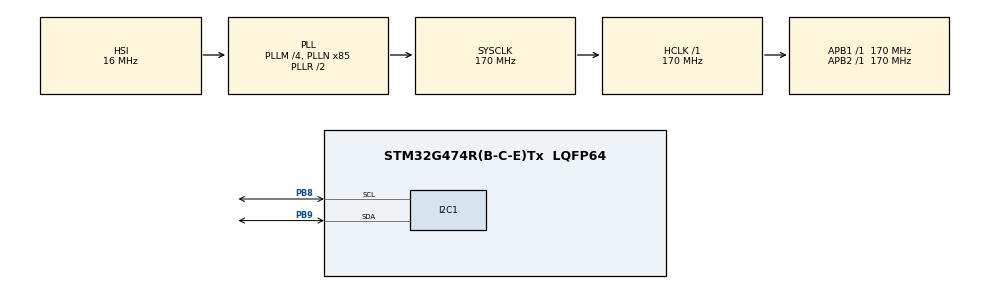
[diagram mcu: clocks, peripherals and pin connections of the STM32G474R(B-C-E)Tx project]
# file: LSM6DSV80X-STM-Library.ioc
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I2C1.Timing=0x40B285C2
Mcu.Family=STM32G4
Mcu.Name=STM32G474R(B-C-E)Tx
Mcu.Package=LQFP64
NUCLEO-G474RE.BUTTON=1
NUCLEO-G474RE.LD2=true
NUCLEO-G474RE.VCP=true
NVIC.EXTI15_10_IRQn=true\:0\:0\:false\:false\:true\:false\:true\:true
NVIC.PriorityGroup=NVIC_PRIORITYGROUP_4
PA13.GPIO_Label=T_SWDIO
PA13.Mode=Serial_Wire
PA13.Signal=SYS_JTMS-SWDIO
PA14.GPIO_Label=T_SWCLK
PA14.Mode=Serial_Wire
PA14.Signal=SYS_JTCK-SWCLK
PA2.Signal=LPUART1_TX
PA3.Signal=LPUART1_RX
PB3.GPIO_Label=T_SWO
PB3.Signal=SYS_JTDO-SWO
PB8-BOOT0.GPIO_Pu=GPIO_PULLUP
PB8-BOOT0.GPIO_Speed=GPIO_SPEED_FREQ_VERY_HIGH
PB8-BOOT0.Mode=I2C
PB8-BOOT0.Signal=I2C1_SCL
PB9.GPIO_Pu=GPIO_PULLUP
PB9.GPIO_Speed=GPIO_SPEED_FREQ_VERY_HIGH
PB9.Mode=I2C
PB9.Signal=I2C1_SDA
PC14-OSC32_IN.GPIO_Label=RCC_OSC32_IN
PC14-OSC32_IN.Signal=RCC_OSC32_IN
PC15-OSC32_OUT.GPIO_Label=RCC_OSC32_OUT
PC15-OSC32_OUT.Signal=RCC_OSC32_OUT
PF0-OSC_IN.GPIO_Label=RCC_OSC_IN
PF0-OSC_IN.Signal=RCC_OSC_IN
PF1-OSC_OUT.GPIO_Label=RCC_OSC_OUT
PF1-OSC_OUT.Signal=RCC_OSC_OUT
ProjectManager.HeapSize=0x200
ProjectManager.StackSize=0x400
ProjectManager.TargetToolchain=CMake
RCC.ADC12Freq_Value=170000000
RCC.ADC345Freq_Value=170000000
RCC.AHBFreq_Value=170000000
RCC.APB1Freq_Value=170000000
RCC.APB1TimFreq_Value=170000000
RCC.APB2Freq_Value=170000000
RCC.APB2TimFreq_Value=170000000
RCC.CortexFreq_Value=170000000
RCC.EXTERNAL_CLOCK_VALUE=12288000
RCC.HCLKFreq_Value=170000000
RCC.HSE_VALUE=24000000
RCC.HSI48_VALUE=48000000
RCC.HSI_VALUE=16000000
RCC.LSE_VALUE=32768
RCC.PLLM=RCC_PLLM_DIV4
RCC.PLLN=85
RCC.RTCClockSelection=RCC_RTCCLKSOURCE_LSE
RCC.SYSCLKFreq_VALUE=170000000
RCC.SYSCLKSource=RCC_SYSCLKSOURCE_PLLCLK
RCC.USBFreq_Value=170000000
RCC.VCOOutputFreq_Value=340000000
VP_NUCLEO-G474RE_VS_BSP_COMMON.Mode=COMMON
VP_SYS_VS_DBSignals.Mode=DisableDeadBatterySignals
board=NUCLEO-G474RE

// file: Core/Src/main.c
/* USER CODE BEGIN Header */
/**
  ******************************************************************************
  * @file           : main.c
  * @brief          : Main program body
  ******************************************************************************
  * @attention
  *
  * Copyright (c) 2026 STMicroelectronics.
  * All rights reserved.
  *
  * This software is licensed under terms that can be found in the LICENSE file
  * in the root directory of this software component.
  * If no LICENSE file comes with this software, it is provided AS-IS.
  *
  ******************************************************************************
  */
/* USER CODE END Header */
#include "main.h"
#include "imu_sensor_read.h"

COM_InitTypeDef BspCOMInit;
I2C_HandleTypeDef hi2c1;

void SystemClock_Config(void);
static void MX_GPIO_Init(void);
static void MX_I2C1_Init(void);

int main(void)
{

  /* MCU Configuration--------------------------------------------------------*/

  /* Reset of all peripherals, Initializes the Flash interface and the Systick. */
  HAL_Init();

  /* Configure the system clock */
  SystemClock_Config();

  /* Initialize all configured peripherals */
  MX_GPIO_Init();
  MX_I2C1_Init();

  /* Initialize led */
  BSP_LED_Init(LED_GREEN);

  /* Initialize USER push-button, will be used to trigger an interrupt each time it's pressed.*/
  BSP_PB_Init(BUTTON_USER, BUTTON_MODE_EXTI);

  /* Initialize COM1 port (115200, 8 bits (7-bit data + 1 stop bit), no parity */
  BspCOMInit.BaudRate   = 115200;
  BspCOMInit.WordLength = COM_WORDLENGTH_8B;
  BspCOMInit.StopBits   = COM_STOPBITS_1;
  BspCOMInit.Parity     = COM_PARITY_NONE;
  BspCOMInit.HwFlowCtl  = COM_HWCONTROL_NONE;
  if (BSP_COM_Init(COM1, &BspCOMInit) != BSP_ERROR_NONE)
  {
    Error_Handler();
  }

  /* Infinite loop */
  /* USER CODE BEGIN WHILE */

  imuSetConfigRegs(&hi2c1);

  while (1)
  {

    (freefallDetection(&hi2c1)) ? printf("you are in freefall :O \n\n\r") : printf("you are not falling :3 \n\n\r");
    (hgShockDetect(&hi2c1)) ? printf("Hit the ground X( \n\n\r") : printf("Not colliding :) \n\n\r");
    // (sixDChangeDetection(&hi2c1)) ? printf("direction changed :D \n\n\r") : printf("direction didnt change :( \n\n\r");
    // printf("the orientation is %i\n\n\n\r", checkOrintation(&hi2c1));

    // // Print all gyro values
    // printf("the gyro X value is %f\n\r", readGyroX(&hi2c1));
    // printf("the gyro Y value is %f\n\r", readGyroY(&hi2c1));
    // printf("the gyro Z value is %f\n\n\r", readGyroZ(&hi2c1));

    // // Print all accel values
    printf("the accel X value is %f\n\r", readAccelX(&hi2c1));
    printf("the accel Y value is %f\n\r", readAccelY(&hi2c1));
    printf("the accel Z value is %f\n\n\n\r", readAccelZ(&hi2c1));

    // // Print temp value
    // printf("the temp value is %f\n\n\n\r", readTempIMU(&hi2c1));

    printf("the HG accel X value is %f\n\r", readHGAccelX(&hi2c1));
    printf("the HG accel Y value is %f\n\r", readHGAccelY(&hi2c1));
    printf("the HG accel Z value is %f\n\n\n\r", readHGAccelZ(&hi2c1));

    // uint16_t regTest = 0x4E;
    // uint8_t readreg;
    // uint16_t regTest2 = 0x45;
    // uint8_t readreg2;
    // uint16_t regTest3 = 0x47;
    // uint8_t readreg3;

     // Test registry. Uncomment as needed. Nothing is enabled to accomodate. Currently viewing settings for ctrl1
	  // HAL_I2C_Mem_Read(&hi2c1, ADDR_READ, regTest, 1, &readreg, 1, 1000);
	  // printf("The value is %x\n\n\n\r", readreg);
	  // readreg = 0;

    //  // Test registry. Uncomment as needed. Nothing is enabled to accomodate. Currently viewing settings for ctrl1
	  // HAL_I2C_Mem_Read(&hi2c1, ADDR_READ, regTest2, 1, &readreg2, 1, 1000);
	  // printf("The value is %x\n\n\n\r", readreg2);
	  // readreg2 = 0;

    // HAL_I2C_Mem_Read(&hi2c1, ADDR_READ, regTest3, 1, &readreg3, 1, 1000);
	  // printf("The value is %x\n\n\n\r", readreg3);
	  // readreg3 = 0;

	  HAL_Delay(250);

    /* USER CODE END WHILE */

  }
}

void SystemClock_Config(void)
{
  RCC_OscInitTypeDef RCC_OscInitStruct = {0};
  RCC_ClkInitTypeDef RCC_ClkInitStruct = {0};

  /** Configure the main internal regulator output voltage
  */
  HAL_PWREx_ControlVoltageScaling(PWR_REGULATOR_VOLTAGE_SCALE1_BOOST);

  /** Initializes the RCC Oscillators according to the specified parameters
  * in the RCC_OscInitTypeDef structure.
  */
  RCC_OscInitStruct.OscillatorType = RCC_OSCILLATORTYPE_HSI;
  RCC_OscInitStruct.HSIState = RCC_HSI_ON;
  RCC_OscInitStruct.HSICalibrationValue = RCC_HSICALIBRATION_DEFAULT;
  RCC_OscInitStruct.PLL.PLLState = RCC_PLL_ON;
  RCC_OscInitStruct.PLL.PLLSource = RCC_PLLSOURCE_HSI;
  RCC_OscInitStruct.PLL.PLLM = RCC_PLLM_DIV4;
  RCC_OscInitStruct.PLL.PLLN = 85;
  RCC_OscInitStruct.PLL.PLLP = RCC_PLLP_DIV2;
  RCC_OscInitStruct.PLL.PLLQ = RCC_PLLQ_DIV2;
  RCC_OscInitStruct.PLL.PLLR = RCC_PLLR_DIV2;
  if (HAL_RCC_OscConfig(&RCC_OscInitStruct) != HAL_OK)
  {
    Error_Handler();
  }

  /** Initializes the CPU, AHB and APB buses clocks
  */
  RCC_ClkInitStruct.ClockType = RCC_CLOCKTYPE_HCLK|RCC_CLOCKTYPE_SYSCLK
                              |RCC_CLOCKTYPE_PCLK1|RCC_CLOCKTYPE_PCLK2;
  RCC_ClkInitStruct.SYSCLKSource = RCC_SYSCLKSOURCE_PLLCLK;
  RCC_ClkInitStruct.AHBCLKDivider = RCC_SYSCLK_DIV1;
  RCC_ClkInitStruct.APB1CLKDivider = RCC_HCLK_DIV1;
  RCC_ClkInitStruct.APB2CLKDivider = RCC_HCLK_DIV1;

  if (HAL_RCC_ClockConfig(&RCC_ClkInitStruct, FLASH_LATENCY_4) != HAL_OK)
  {
    Error_Handler();
  }
}

static void MX_I2C1_Init(void)
{

  hi2c1.Instance = I2C1;
  hi2c1.Init.Timing = 0x40B285C2;
  hi2c1.Init.OwnAddress1 = 0;
  hi2c1.Init.AddressingMode = I2C_ADDRESSINGMODE_7BIT;
  hi2c1.Init.DualAddressMode = I2C_DUALADDRESS_DISABLE;
  hi2c1.Init.OwnAddress2 = 0;
  hi2c1.Init.OwnAddress2Masks = I2C_OA2_NOMASK;
  hi2c1.Init.GeneralCallMode = I2C_GENERALCALL_DISABLE;
  hi2c1.Init.NoStretchMode = I2C_NOSTRETCH_DISABLE;
  if (HAL_I2C_Init(&hi2c1) != HAL_OK)
  {
    Error_Handler();
  }

  /** Configure Analogue filter
  */
  if (HAL_I2CEx_ConfigAnalogFilter(&hi2c1, I2C_ANALOGFILTER_ENABLE) != HAL_OK)
  {
    Error_Handler();
  }

  /** Configure Digital filter
  */
  if (HAL_I2CEx_ConfigDigitalFilter(&hi2c1, 0) != HAL_OK)
  {
    Error_Handler();
  }

}

static void MX_GPIO_Init(void)
{

  /* GPIO Ports Clock Enable */
  __HAL_RCC_GPIOC_CLK_ENABLE();
  __HAL_RCC_GPIOF_CLK_ENABLE();
  __HAL_RCC_GPIOA_CLK_ENABLE();
  __HAL_RCC_GPIOB_CLK_ENABLE();

}

void Error_Handler(void)
{
  __disable_irq();
  while (1)
  {
  }
}
